# ATA5835 device description
Architecture: AVR8; Family: megaAVR
Registers are 8-bit, access not given, no defined reset value unless marked. A register's access mark holds for its fields unless they carry their own. Offsets are from the block's base; [hi:lo] are bit positions; {n}, {i} and the like mark numbered series.

## DFIFO
Instances: DFIFO 0x00
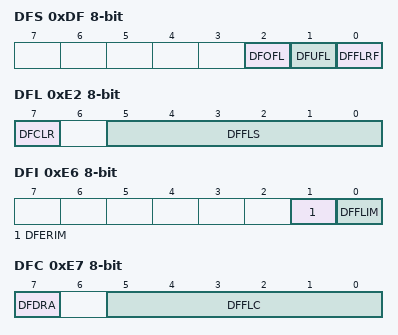
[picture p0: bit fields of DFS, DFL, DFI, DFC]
0xDF DFS — Data FIFO Status
  [2] DFOFL — Data FIFO Overflow Flag
  [1] DFUFL — Data FIFO Underflow Flag
  [0] DFFLRF — Data FIFO Fill Level Reached Status Flag
0xE0 DFTL 16-bit bits used 11:0 — Data FIFO Telegram Length
0xE2 DFL — Data FIFO Fill Level
  [7] DFCLR — Data FIFO Clear
  [5:0] DFFLS — Data FIFO Fill Level Status
0xE3 DFWP bits used 4:0 — Data FIFO Write Pointer
0xE4 DFRP bits used 5:0 — Data FIFO Read Pointer
0xE5 DFD — Data FIFO Data
0xE6 DFI — Data FIFO Interrupt Mask
  [1] DFERIM — Data FIFO Error Interrupt Mask
  [0] DFFLIM — Data FIFO Fill Level Interrupt Mask
0xE7 DFC — Data FIFO Configuration
  [7] DFDRA — Data FIFO Direct Read Access Operational Mode
  [5:0] DFFLC — Data FIFO Fill Level Configuration

## EEPROM
Instances: EEPROM 0x00
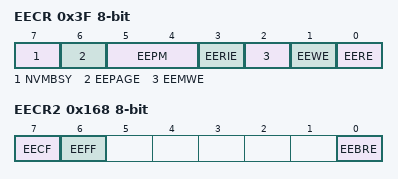
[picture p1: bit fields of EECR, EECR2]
0x3F EECR — EEPROM Control Register
  [7] NVMBSY — Non-Volatile Memory Busy
  [6] EEPAGE — EEPROM Page Access
  [5:4] EEPM — EEPROM Programming Mode
    0=ERASE_AND_WRITE_IN_ONE_OPERATION; 1=ERASE_ONLY; 2=WRITE_ONLY
  [3] EERIE — EEPROM Ready Interrupt Enable
  [2] EEMWE — EEPROM Master Write Enable
  [1] EEWE — EEPROM Write Enable
  [0] EERE — EEPROM Read Enable
0x40 EEDR — EEPROM Data Register
0x41 EEAR 16-bit bits used 10:0 — EEPROM Address Register
0x43 EEPR — EEPROM Protect Register
  [3:0] EEAP — EEPROM Access Protect
0x168 EECR2 — EEPROM Control Register 2
  [7] EECF — EEPROM Error Correction Flag
  [6] EEFF — EEPROM Error Fault Flag
  [0] EEBRE — EEPROM Burst Read Enable
0x169 PGMST — Program Memory Status Register
  [4:0] PGMSYN — Program Memory Syndrome
0x16A EEST — EEPROM Status Register
  [3:0] EESYN — EEPROM Syndrome

## FE
Instances: FE 0x00
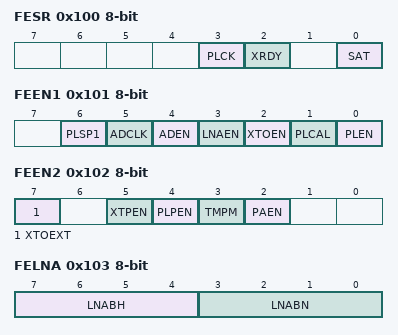
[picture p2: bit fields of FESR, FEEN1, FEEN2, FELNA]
0x100 FESR — RF Front End Status Register
  [3] PLCK — PLL Locked
  [2] XRDY — XTO Ready
  [0] SAT — LNA Saturated
0x101 FEEN1 — RF Front End Enable 1
  [6] PLSP1 — PLL Speedup 1
  [5] ADCLK — ADC Clock Enable
  [4] ADEN — Analog Digital Converter Enable
  [3] LNAEN — Low Noise Amplifier Enable
  [2] XTOEN — Crystal Oscillator Enable
  [1] PLCAL — PLL Calibration Mode
  [0] PLEN — PLL Enable
0x102 FEEN2 — RF Front End Enable 2
  [7] XTOEXT — XTO External Clock
  [5] XTPEN — XTO Voltage Pump Enable
  [4] PLPEN — PLL Post Enable
  [3] TMPM — Temperature Measurement
  [2] PAEN — Power Amplifier Enable
0x103 FELNA — RF Front End LNA Bias
  [7:4] LNABH — LNA Bias High Sense Mode
  [3:0] LNABN — LNA Bias Normal Sense Mode
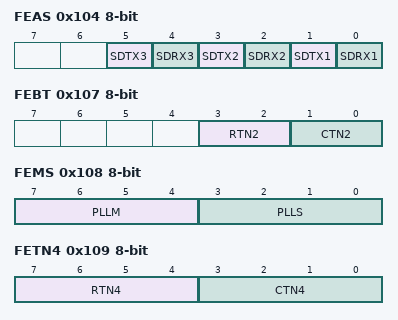
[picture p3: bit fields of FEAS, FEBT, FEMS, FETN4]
0x104 FEAS — RF Front End Antenna Switch
  [5] SDTX3 — SPDT RF Switch Tx 3
  [4] SDRX3 — SPDT RF Switch Rx 3
  [3] SDTX2 — SPDT RF Switch Tx 2
  [2] SDRX2 — SPDT RF Switch Rx 2
  [1] SDTX1 — SPDT RF Switch Tx 1
  [0] SDRX1 — SPDT RF Switch Rx 1
0x105 FEPAC — RF Front End Power Amplifier Control
  [7:0] FEPAC
    0=_11_80_12_90; 1=_11_30_12_33; 2=_10_70_11_76; 3=_10_20_11_10; 4=_9_70_10_60; 5=_9_20_10_00; 6=_8_60_9_50; 7=_8_00_9_00; 8=_7_50_8_50; 9=_7_00_7_90; 10=_6_40_7_30; 11=_5_90_6_80; 12=_5_30_6_30; 13=_4_77_5_70; 14=_4_17_5_20; 15=_3_67_4_60; 16=_3_12_4_07; 17=_2_56_3_47; 18=_2_10_2_97; 19=_1_58_2_42; 20=_1_08_1_86; 21=_0_50_1_40; 22=_0_00_0_88; 23=_0_41_0_38; 24=_1_00_0_20; 25=_1_42_0_70; 26=_1_83_1_11; 27=_2_42_1_70; 28=_2_88_2_12; 29=_3_38_2_53; 30=_3_81_3_12; 31=_4_31_3_58; 32=_4_72_4_08; 33=_5_09_4_51; 34=_5_57_5_01; 35=_6_00_5_42; 36=_6_41_5_79; 37=_6_77_6_27; 38=_7_19_6_70; 39=_7_55_7_11; 40=_7_98_7_47; 41=_8_40_7_89; 42=_8_79_8_25; 43=_9_11_8_68; 44=_9_46_9_10; 45=_9_82_9_49; 46=_10_18_9_81; 47=_10_60_10_16; 48=_10_89_10_52; 49=_11_30_10_88; 50=_11_62_11_30; 51=_12_06_11_59; 52=_12_39_12_00; 53=_12_82_12_32; 54=_13_22_12_76; 55=_13_58_13_09; 56=_13_95_13_52; 57=_14_22_13_92; 58=_14_41_14_28; 59=_14_49_14_65; {v}=_14_60_14_65 (v=60..63)
0x106 FEVCT bits used 3:0 — RF Front End VCO Tuning
0x107 FEBT — RF Front End RC Tuning
  [3:2] RTN2 — 2 Bit Resistor Tuning
  [1:0] CTN2 — 2 Bit Capacitor Tuning
0x108 FEMS — RF Front End Main and Swallow Counter
  [7:4] PLLM — PLL Main
  [3:0] PLLS — PLL Swallow
0x109 FETN4 — RF Front End RC Tuning 4bit Register
  [7:4] RTN4 — 4 Bit Resistor Tuning
  [3:0] CTN4 — 4 Bit Capacitor Tuning
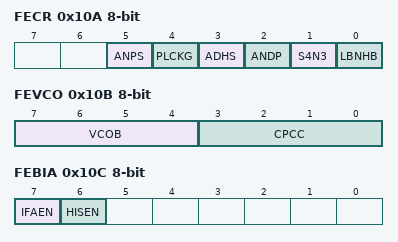
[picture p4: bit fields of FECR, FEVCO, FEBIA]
0x10A FECR — RF Front End Control Register
  [5] ANPS — ASK Not DPSK Switch
  [4] PLCKG — PLL Lock Detect Gate
  [3] ADHS — ADC High Sample Rate
  [2] ANDP — Antenna Damping
  [1] S4N3 — Select 433MHz Not 315MHz Band
  [0] LBNHB — Low-Band Not High-Band
0x10B FEVCO — RF Front End VCO and PLL Control
  [7:4] VCOB — VCO Bias
  [3:0] CPCC — Charge Pump Current Control
0x10C FEBIA — RF Front End Amplifier Bias
  [7] IFAEN — IF Amplifier Enable
  [6] HISEN — High Sensitivity Enable
0x10D SPARE1 — RF Front End Spare Register 1
  [7:0] CHBIR — Calibration of High Band Image Rejection
